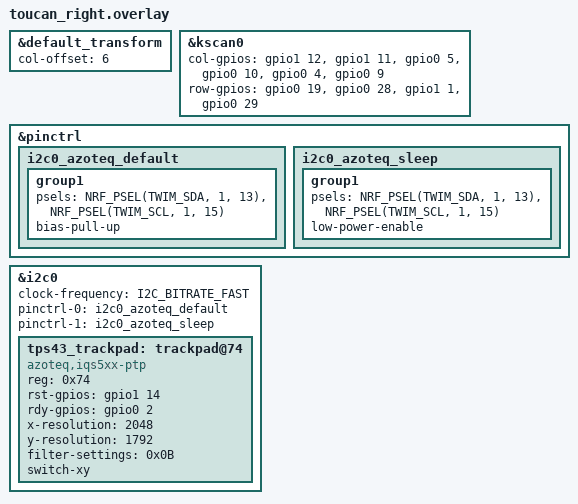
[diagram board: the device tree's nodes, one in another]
#include "toucan.dtsi"

&default_transform {
    col-offset = <6>;
};

&kscan0 {
    col-gpios
    = <&gpio1 12 GPIO_ACTIVE_HIGH>
    , <&gpio1 11 GPIO_ACTIVE_HIGH>
    , <&gpio0 5 GPIO_ACTIVE_HIGH>
    , <&gpio0 10 GPIO_ACTIVE_HIGH>
    , <&gpio0 4 GPIO_ACTIVE_HIGH>
    , <&gpio0 9 GPIO_ACTIVE_HIGH>
    ;

    row-gpios
    = <&gpio0 19 (GPIO_ACTIVE_HIGH | GPIO_PULL_DOWN)>
    , <&gpio0 28 (GPIO_ACTIVE_HIGH | GPIO_PULL_DOWN)>
    , <&gpio1 1 (GPIO_ACTIVE_HIGH | GPIO_PULL_DOWN)>
    , <&gpio0 29 (GPIO_ACTIVE_HIGH | GPIO_PULL_DOWN)>
    ;
};

&pinctrl {
    i2c0_azoteq_default: i2c0_azoteq_default {
        group1 {
            psels = <NRF_PSEL(TWIM_SDA, 1, 13)>,
                    <NRF_PSEL(TWIM_SCL, 1, 15)>;
            bias-pull-up;
        };
    };

    i2c0_azoteq_sleep: i2c0_azoteq_sleep {
        group1 {
            psels = <NRF_PSEL(TWIM_SDA, 1, 13)>,
                    <NRF_PSEL(TWIM_SCL, 1, 15)>;
            low-power-enable;
        };
    };
};

&i2c0 {
   status = "okay";
    clock-frequency = <I2C_BITRATE_FAST>;
    pinctrl-0 = <&i2c0_azoteq_default>;
    pinctrl-1 = <&i2c0_azoteq_sleep>;
    pinctrl-names = "default", "sleep";

    tps43_trackpad: trackpad@74 {
        compatible = "azoteq,iqs5xx-ptp";
        reg = <0x74>;
        status = "okay";

        rst-gpios = <&gpio1 14 GPIO_ACTIVE_HIGH>;
        rdy-gpios = <&gpio0 2 GPIO_ACTIVE_HIGH>;

        x-resolution = <2048>;
        y-resolution = <1792>;
        filter-settings = <0x0B>;
        switch-xy;
    };
};
